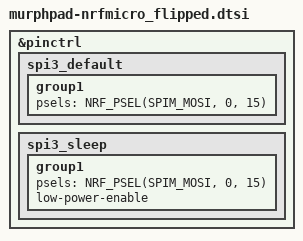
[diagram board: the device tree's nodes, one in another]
/*
 * Copyright (c) 2024 The ZMK Contributors
 *
 * SPDX-License-Identifier: MIT
 */

#include "murphpad-nrf52.dtsi"

&pinctrl {
    spi3_default: spi3_default {
        group1 {
            psels = <NRF_PSEL(SPIM_MOSI, 0, 15)>;
        };
    };

    spi3_sleep: spi3_sleep {
        group1 {
            psels = <NRF_PSEL(SPIM_MOSI, 0, 15)>;
            low-power-enable;
        };
    };
};
